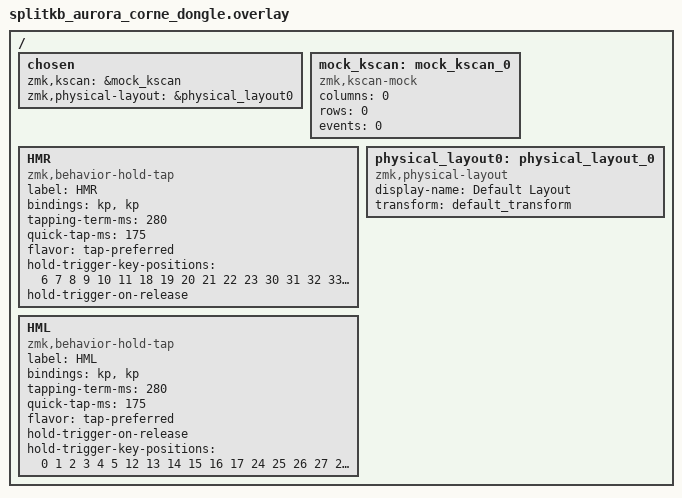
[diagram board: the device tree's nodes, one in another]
#include <dt-bindings/zmk/matrix_transform.h>

/ {
    chosen {
        zmk,kscan = &mock_kscan;
        zmk,physical-layout = &physical_layout0;
    };

    mock_kscan: mock_kscan_0 {
        compatible = "zmk,kscan-mock";
        columns = <0>;
        rows = <0>;
        events = <0>;
    };

    HMR: HMR {
            compatible = "zmk,behavior-hold-tap";
            label = "HMR";
            bindings = <&kp>, <&kp>;

            #binding-cells = <2>;
            tapping-term-ms = <280>;
            quick-tap-ms = <175>;
            flavor = "tap-preferred";
            hold-trigger-key-positions = <6 7 8 9 10 11 18 19 20 21 22 23 30 31 32 33 34 35 39 40 41 36 37 38>;
            hold-trigger-on-release;
        };

    HML: HML {
        compatible = "zmk,behavior-hold-tap";
        label = "HML";
        bindings = <&kp>, <&kp>;

        #binding-cells = <2>;
        tapping-term-ms = <280>;
        quick-tap-ms = <175>;
        flavor = "tap-preferred";
        hold-trigger-on-release;
        hold-trigger-key-positions = <0 1 2 3 4 5 12 13 14 15 16 17 24 25 26 27 28 29 36 37 38 39 40 41>;
    };

    physical_layout0: physical_layout_0 {
        compatible = "zmk,physical-layout";
        display-name = "Default Layout";
        transform = <&default_transform>;
    };
};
